# STM32MP25_CM33 register map
File version: 1.3
CPU: CM33 r0p1, little endian, MPU, FPU, vendor SysTick, 8 interrupt priority bits
Registers are 32-bit, read-write, reset 0x0 unless marked. A register's access mark holds for its fields unless they carry their own. Offsets are from the block's base; [hi:lo] are bit positions; {n}, {i} and the like mark numbered series; 'fields as' and 'values as' point back to an identical list.

## EXTI1 (part 1 of 2) — EXTI1 address block description
Base 0x44220000
Same registers: EXTI1_S 0x54220000
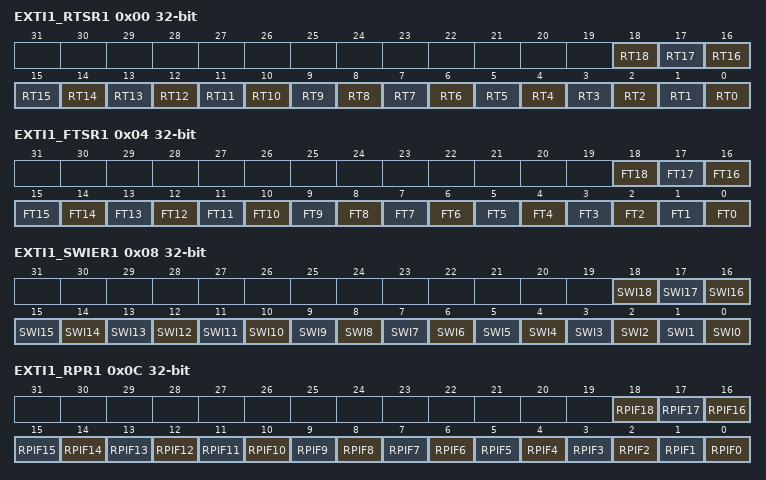
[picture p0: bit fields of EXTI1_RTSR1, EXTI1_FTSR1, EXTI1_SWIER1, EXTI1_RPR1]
0x00 EXTI1_RTSR1 — EXTI1 rising trigger selection register
  [all] fields
    0=Rising trigger disabled (for event and interrupt) for input line; 1=Rising trigger enabled (for event and interrupt) for input line
  [n] RT{n} (n=0..18) — Rising trigger event configuration bit of configurable event input x When SECx is disabled in EXTI1_SECCFGR1, RTx can be accessed with non-secure and secure access. When SECx is enabled in EXTI1_SECCFGR1, RTx can only be accessed with secure access. Non-secure write to RTx is discarded. Non-secure read returns 0. When PRIVx is disabled in EXTI1_PRIVCFGR1, RTx can be accessed with unprivileged and privileged access. When PRIVx is enabled in EXTI1_PRIVCFGR1, RTx can only be accessed with privileged access. Unprivileged write to RTx is discarded. Unprivileged read returns 0. When CID filtering is disabled in EXTI1_ExCIDCFGR, RTx can be accessed by any processor CID. When CID filtering is enabled in EXTI1_ExCIDCFGR, RTx can only be accessed by the allowed processor CID. Illegal CID write to RTx is discarded, and read returns 0. Note: The configurable event input is edge triggered. No glitch must be generated on this input. If a rising edge on the configurable event input occurs while writing to the register, the associated pending bit is not set. Note: Rising and falling edge triggers can be set for the same configurable event input. In this case, both edges generate a trigger.
0x04 EXTI1_FTSR1 — EXTI1 falling trigger selection register
  [all] fields
    0=Falling trigger disabled (for event and interrupt) for input line; 1=Falling trigger enabled (for event and interrupt) for input line
  [n] FT{n} (n=0..18) — Falling trigger event configuration bit of configurable event input x When SECx is disabled in EXTI1_SECCFGR1, FTx can be accessed with non-secure and secure access. When SECx is enabled in EXTI1_SECCFGR1, FTx can only be accessed with secure access. Non-secure write to FTx is discarded. Non-secure read returns 0. When PRIVx is disabled in EXTI1_PRIVCFGR1, FTx can be accessed with unprivileged and privileged access. When PRIVx is enabled in EXTI1_PRIVCFGR1, FTx can only be accessed with privileged access. Unprivileged write to FTx is discarded. Unprivileged read returns 0. When CID filtering is disabled in EXTI1_ExCIDCFGR, FTx can be accessed by any processor CID. When CID filtering is enabled in EXTI1_ExCIDCFGR, FTx can only be accessed by the allowed processor CID. Dis allowed CID CID write to FTx is discarded, and read returns0. Note: The configurable event input is edge triggered. No glitch must be generated on this input. If a falling edge on the configurable event input occurs while writing to the register, the associated pending bit is not set. Note: Rising and falling edge triggers can be set for the same configurable event input. In this case, both edges generate a trigger.
0x08 EXTI1_SWIER1 — EXTI1 software interrupt event register
  [all] fields
    0=Writing 0 has no effect; 1=Writing 1 to this bit triggers a rising edge event on event x (bit auto cleared byhardware)
  [n] SWI{n} (n=0..18) — Software interrupt on event x When SECx is disabled in EXTI1_SECCFGR1, SWIx can be accessed with non-secure and secure access. When SECx is enabled in EXTI1_SECCFGR1, SWIx can only be accessed with secure access. Non-secure write to SWIx is discarded. Non-secure read returns 0. When PRIVx is disabled in EXTI1_PRIVCFGR1,SWIx can be accessed with unprivileged and privileged access. When PRIVx is enabled in EXTI1_PRIVCFGR1,SWIx can only be accessed with privileged access. Unprivileged write to SWIx is discarded. Unprivileged read returns 0. When CID filtering is disabled in EXTI1_ExCIDCFGR, SWIx can be accessed by any processor CID. When CID filtering is enabled in EXTI1_ExCIDCFGR, SWIx can only be accessed by the allowed processor CID. Dis allowed CID write to SWIx is discarded and read returns0. A software interrupt is generated whatever the setting in EXTI1_RTSR and EXTI1_FTSR. It always returns 0 when read.
0x0C EXTI1_RPR1 — EXTI1 rising edge pending register
  [all] fields
    0=No rising edge trigger request occurred; 1=Rising edge trigger request occurred
  [n] RPIF{n} (n=0..18) — Configurable event input x rising edge pending bit This bit is set when the selected rising edge event or an EXTI1_SWIER software trigger arrives on the configurable event line. This bit is cleared by writing a 1 into the bit. When SECx is disabled in EXTI1_SECCFGR1, RPIFx can be accessed with non-secure and secure access. When SECx is enabled in EXTI1_SECCFGR1, RPIFx can only be accessed with secure access. Non-secure write to RPIFx is discarded. Non-secure read returns 0. When PRIVx is disabled in EXTI1_PRIVCFGR1, RPIFx can be accessed with unprivileged and privileged access. When PRIVx is enabled in EXTI1_PRIVCFGR1, RPIFx can only be accessed with privileged access. Unprivileged write to RPIFx is discarded. Unprivileged read returns 0. When CID filtering is disabled in EXTI1_ExCIDCFGR, RPIFx can be accessed by any processor CID. When CID filtering is enabled in EXTI1_ExCIDCFGR, RPIFx can only be accessed by the allowed processor CID. Dis allowed CID write to RPIFx is discarded, and read returns0.
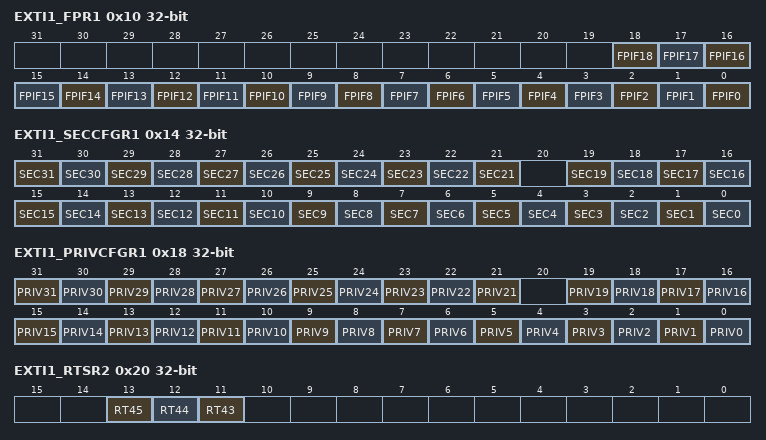
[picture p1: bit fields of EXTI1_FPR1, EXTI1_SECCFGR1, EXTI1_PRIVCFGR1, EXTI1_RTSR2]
0x10 EXTI1_FPR1 — EXTI1 falling edge pending register
  [all] fields
    0=No falling edge trigger request occurred; 1=Falling edge trigger request occurred
  [n] FPIF{n} (n=0..18) — configurable event input x falling edge pending bit This bit is set when the falling edge event arrives on the configurable event line. This bit is cleared by writing a 1 into this bit. When SECx is disabled in EXTI1_SECCFGR1, FPIFx can be accessed with non-secure and secure access. When SECx is enabled in EXTI1_SECCFGR1, FPIFx can only be accessed with secure access. Non-secure write to FPIFx is discarded. Non-secure read returns 0. When PRIVx is disabled in EXTI1_PRIVCFGR1, FPIFx can be accessed with unprivileged and privileged access. When PRIVx is enabled in EXTI1_PRIVCFGR1, FPIFx can only be accessed with privileged access. Unprivileged write to FPIFx is discarded. Unprivileged read returns 0. When CID filtering is disabled in EXTI1_ExCIDCFGR, FPIFx can be accessed by any processor CID. When CID filtering is enabled in EXTI1_ExCIDCFGR, FPIFx can only be accessed by the allowed processor CID. Dis allowed CID write to FPIFx is discarded, and read returns0.
0x14 EXTI1_SECCFGR1 — EXTI1 security configuration register
  [n] SEC{n} (n=21..31) — Security enable on event input x When CID filtering is disabled in EXTI1_ExCIDCFGR, SECx can be accessed by any processor CID. When CID filtering is enabled in EXTI1_ExCIDCFGR, SECx can only be accessed by the allowed processor CID. Dis allowed CID write to SECx is discarded and read returns 0.
    0=Event security disabled (non-secure); 1=Event security enabled (secure)
  [n] SEC{n} (n=0..19) — Security enable on event input x
0x18 EXTI1_PRIVCFGR1 — EXTI1 privilege configuration register
  [n] PRIV{n} (n=21..31) — Privilege enable on event input x When SECx is disabled in EXTI1_SECCFGR1, PRIVx can be accessed with secure and non-secure access. When SECx is enabled in EXTI1_SECCFGR1, PRIVx can only be written with secure access. Non-secure write to PRIVx is discarded. When CID filtering is disabled in EXTI1_ExCIDCFGR, PRIVx can be accessed by any processor CID. When CID filtering is enabled in EXTI1_ExCIDCFGR, PRIVx can only be accessed by the allowed processor CID. Dis allowed CID write to PRIVx is discarded and read returns 0.
    0=Event privilege disabled (unprivileged); 1=Event privilege enabled (privileged)
  [n] PRIV{n} (n=0..19) — Privilege enable on event input x
0x20 EXTI1_RTSR2 — EXTI1 rising trigger selection register
  [all] fields
    0=Rising trigger disabled (for event and Interrupt) for input line x; 1=Rising trigger enabled (for event and Interrupt) for input line x
  [13] RT45 — Rising trigger event configuration bit of configurable event input x When SECx is disabled in EXTI1_SECCFGR2, RTx can be accessed with non-secure and secure access. When SECx is enabled in EXTI1_SECCFGR2, RTx can only be accessed with secure access. Non-secure write to RTx is discarded. Non-secure read returns 0. When PRIVx is disabled in EXTI1_PRIVCFGR2, RTx can be accessed with unprivileged and privileged access. When PRIVx is enabled in EXTI1_PRIVCFGR2, RTx can only be accessed with privileged access. Unprivileged write to RTx is discarded. Unprivileged read returns 0. When CID filtering is disabled in EXTI1_ExCIDCFGR, RTx can be accessed by any processor CID. When CID filtering is enabled in EXTI1_ExCIDCFGR, RTx can only be accessed by the allowed processor CID. Illegal CID write to RTx is discarded and read returns 0. Note: The configurable event input is edge triggered. No glitch must be generated on this input. If a rising edge on the configurable event input occurs while writing to the register, the associated pending bit is not set. Note: Rising and falling edge triggers can be set for the same configurable event input. In this case, both edges generate a trigger.
  [12] RT44 — Rising trigger event configuration bit of configurable event input x When SECx is disabled in EXTI1_SECCFGR2, RTx can be accessed with non-secure and secure access. When SECx is enabled in EXTI1_SECCFGR2, RTx can only be accessed with secure access. Non-secure write to RTx is discarded. Non-secure read returns 0. When PRIVx is disabled in EXTI1_PRIVCFGR2, RTx can be accessed with unprivileged and privileged access. When PRIVx is enabled in EXTI1_PRIVCFGR2, RTx can only be accessed with privileged access. Unprivileged write to RTx is discarded. Unprivileged read returns 0. When CID filtering is disabled in EXTI1_ExCIDCFGR, RTx can be accessed by any processor CID. When CID filtering is enabled in EXTI1_ExCIDCFGR, RTx can only be accessed by the allowed processor CID. Illegal CID write to RTx is discarded and read returns 0. Note: The configurable event input is edge triggered. No glitch must be generated on this input. If a rising edge on the configurable event input occurs while writing to the register, the associated pending bit is not set. Note: Rising and falling edge triggers can be set for the same configurable event input. In this case, both edges generate a trigger.
  [11] RT43 — Rising trigger event configuration bit of configurable event input x When SECx is disabled in EXTI1_SECCFGR2, RTx can be accessed with non-secure and secure access. When SECx is enabled in EXTI1_SECCFGR2, RTx can only be accessed with secure access. Non-secure write to RTx is discarded. Non-secure read returns 0. When PRIVx is disabled in EXTI1_PRIVCFGR2, RTx can be accessed with unprivileged and privileged access. When PRIVx is enabled in EXTI1_PRIVCFGR2, RTx can only be accessed with privileged access. Unprivileged write to RTx is discarded. Unprivileged read returns 0. When CID filtering is disabled in EXTI1_ExCIDCFGR, RTx can be accessed by any processor CID. When CID filtering is enabled in EXTI1_ExCIDCFGR, RTx can only be accessed by the allowed processor CID. Illegal CID write to RTx is discarded and read returns 0. Note: The configurable event input is edge triggered. No glitch must be generated on this input. If a rising edge on the configurable event input occurs while writing to the register, the associated pending bit is not set. Note: Rising and falling edge triggers can be set for the same configurable event input. In this case, both edges generate a trigger.
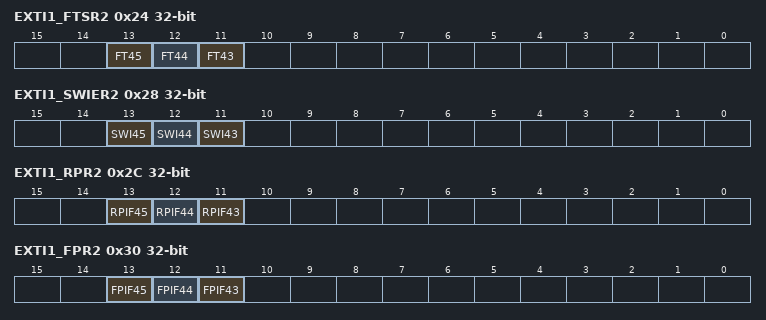
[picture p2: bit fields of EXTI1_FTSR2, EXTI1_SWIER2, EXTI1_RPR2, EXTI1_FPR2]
0x24 EXTI1_FTSR2 — EXTI1 falling trigger selection register
  [all] fields
    0=Falling trigger disabled (for event and Interrupt) for input line; 1=Falling trigger enabled (for event and Interrupt) for input line
  [13] FT45 — Falling trigger event configuration bit of configurable event input x When SECx is disabled in EXTI1_SECCFGR2, FTx can be accessed with non-secure and secure access. When SECx is enabled in EXTI1_SECCFGR2, FTx can only be accessed with secure access. Non-secure write to FTx is discarded. Non-secure read returns 0. When PRIVx is disabled in EXTI1_PRIVCFGR2, FTx can be accessed with unprivileged and privileged access. When PRIVx is enabled in EXTI1_PRIVCFGR2, FTx can only be accessed with privileged access. Unprivileged write to FTx is discarded. Unprivileged read returns 0. When CID filtering is disabled in EXTI1_ExCIDCFGR, FTx can be accessed by any processor CID. When CID filtering is enabled in EXTI1_ExCIDCFGR, FTx can only be accessed by the allowed processor CID. Dis allowed CID write to FTx is discarded and read returns 0. Note: The configurable event input is edge triggered. No glitch must be generated on this input. If a falling edge on the configurable event input occurs while writing to the register, the associated pending bit is not set. Note: Rising and falling edge triggers can be set for the same configurable event input. In this case, both edges generate a trigger.
  [12] FT44 — Falling trigger event configuration bit of configurable event input x When SECx is disabled in EXTI1_SECCFGR2, FTx can be accessed with non-secure and secure access. When SECx is enabled in EXTI1_SECCFGR2, FTx can only be accessed with secure access. Non-secure write to FTx is discarded. Non-secure read returns 0. When PRIVx is disabled in EXTI1_PRIVCFGR2, FTx can be accessed with unprivileged and privileged access. When PRIVx is enabled in EXTI1_PRIVCFGR2, FTx can only be accessed with privileged access. Unprivileged write to FTx is discarded. Unprivileged read returns 0. When CID filtering is disabled in EXTI1_ExCIDCFGR, FTx can be accessed by any processor CID. When CID filtering is enabled in EXTI1_ExCIDCFGR, FTx can only be accessed by the allowed processor CID. Dis allowed CID write to FTx is discarded and read returns 0. Note: The configurable event input is edge triggered. No glitch must be generated on this input. If a falling edge on the configurable event input occurs while writing to the register, the associated pending bit is not set. Note: Rising and falling edge triggers can be set for the same configurable event input. In this case, both edges generate a trigger.
  [11] FT43 — Falling trigger event configuration bit of configurable event input x When SECx is disabled in EXTI1_SECCFGR2, FTx can be accessed with non-secure and secure access. When SECx is enabled in EXTI1_SECCFGR2, FTx can only be accessed with secure access. Non-secure write to FTx is discarded. Non-secure read returns 0. When PRIVx is disabled in EXTI1_PRIVCFGR2, FTx can be accessed with unprivileged and privileged access. When PRIVx is enabled in EXTI1_PRIVCFGR2, FTx can only be accessed with privileged access. Unprivileged write to FTx is discarded. Unprivileged read returns 0. When CID filtering is disabled in EXTI1_ExCIDCFGR, FTx can be accessed by any processor CID. When CID filtering is enabled in EXTI1_ExCIDCFGR, FTx can only be accessed by the allowed processor CID. Dis allowed CID write to FTx is discarded and read returns 0. Note: The configurable event input is edge triggered. No glitch must be generated on this input. If a falling edge on the configurable event input occurs while writing to the register, the associated pending bit is not set. Note: Rising and falling edge triggers can be set for the same configurable event input. In this case, both edges generate a trigger.
0x28 EXTI1_SWIER2 — EXTI1 software interrupt event register
  [all] fields
    0=Writing 0 has no effect; 1=Writing 1 to this bit triggers a rising edge event on event x (bit auto cleared by hardware)
  [13] SWI45 — Software interrupt on event x When SECx is disabled in EXTI1_SECCFGR2, SWIx can be accessed with non-secure and secure access. When SECx is enabled in EXTI1_SECCFGR2, SWIx can only be accessed with secure access. Non-secure write to SWIx is discarded. Non-secure read returns 0. When PRIVx is disabled in EXTI1_PRIVCFGR2, SWIx can be accessed with unprivileged and privileged access. When PRIVx is enabled in EXTI1_PRIVCFGR2, SWIx can only be accessed with privileged access. Unprivileged write to SWIx is discarded. Unprivileged read returns 0. When CID filtering is disabled in EXTI1_ExCIDCFGR, SWIx can be accessed by any processor CID. When CID filtering is enabled in EXTI1_ExCIDCFGR, SWIx can only be accessed by the allowed processor CID. Dis allowed CID write to SWIx is discarded and read returns 0. A software interrupt is generated whatever the setting in EXTI1_RTSR and EXTI1_FTSR. It always returns 0 when read.
  [12] SWI44 — Software interrupt on event x When SECx is disabled in EXTI1_SECCFGR2, SWIx can be accessed with non-secure and secure access. When SECx is enabled in EXTI1_SECCFGR2, SWIx can only be accessed with secure access. Non-secure write to SWIx is discarded. Non-secure read returns 0. When PRIVx is disabled in EXTI1_PRIVCFGR2, SWIx can be accessed with unprivileged and privileged access. When PRIVx is enabled in EXTI1_PRIVCFGR2, SWIx can only be accessed with privileged access. Unprivileged write to SWIx is discarded. Unprivileged read returns 0. When CID filtering is disabled in EXTI1_ExCIDCFGR, SWIx can be accessed by any processor CID. When CID filtering is enabled in EXTI1_ExCIDCFGR, SWIx can only be accessed by the allowed processor CID. Dis allowed CID write to SWIx is discarded and read returns 0. A software interrupt is generated whatever the setting in EXTI1_RTSR and EXTI1_FTSR. It always returns 0 when read.
  [11] SWI43 — Software interrupt on event x When SECx is disabled in EXTI1_SECCFGR2, SWIx can be accessed with non-secure and secure access. When SECx is enabled in EXTI1_SECCFGR2, SWIx can only be accessed with secure access. Non-secure write to SWIx is discarded. Non-secure read returns 0. When PRIVx is disabled in EXTI1_PRIVCFGR2, SWIx can be accessed with unprivileged and privileged access. When PRIVx is enabled in EXTI1_PRIVCFGR2, SWIx can only be accessed with privileged access. Unprivileged write to SWIx is discarded. Unprivileged read returns 0. When CID filtering is disabled in EXTI1_ExCIDCFGR, SWIx can be accessed by any processor CID. When CID filtering is enabled in EXTI1_ExCIDCFGR, SWIx can only be accessed by the allowed processor CID. Dis allowed CID write to SWIx is discarded and read returns 0. A software interrupt is generated whatever the setting in EXTI1_RTSR and EXTI1_FTSR. It always returns 0 when read.
0x2C EXTI1_RPR2 — EXTI1 rising edge pending register
  [all] fields
    values as the fields of EXTI1_RPR1
  [13] RPIF45 — Configurable event input x rising edge pending bit This bit is set when the selected rising edge event or an EXTI1_SWIER software trigger arrives on the configurable event line. This bit is cleared by writing a 1 into the bit. When SECx is disabled in EXTI1_SECCFGR2, RPIFx can be accessed with non-secure and secure access. When SECx is enabled in EXTI1_SECCFGR2, RPIFx can only be accessed with secure access. Non-secure write to RPIFx is discarded. Non-secure read returns 0. When PRIVx is disabled in EXTI1_PRIVCFGR2, RPIFx can be accessed with unprivileged and privileged access. When PRIVx is enabled in EXTI1_PRIVCFGR2, this bit can only be accessed with privileged access. Unprivileged write to RPIFx is discarded. Unprivileged read returns 0. When CID filtering is disabled in EXTI1_ExCIDCFGR, RPIFx can be accessed by any processor CID. When CID filtering is enabled in EXTI1_ExCIDCFGR, this bit can only be accessed by the allowed processor CID. Dis allowed CID write to RPIFx is discarded and read returns 0.
  [12] RPIF44 — Configurable event input x rising edge pending bit This bit is set when the selected rising edge event or an EXTI1_SWIER software trigger arrives on the configurable event line. This bit is cleared by writing a 1 into the bit. When SECx is disabled in EXTI1_SECCFGR2, RPIFx can be accessed with non-secure and secure access. When SECx is enabled in EXTI1_SECCFGR2, RPIFx can only be accessed with secure access. Non-secure write to RPIFx is discarded. Non-secure read returns 0. When PRIVx is disabled in EXTI1_PRIVCFGR2, RPIFx can be accessed with unprivileged and privileged access. When PRIVx is enabled in EXTI1_PRIVCFGR2, this bit can only be accessed with privileged access. Unprivileged write to RPIFx is discarded. Unprivileged read returns 0. When CID filtering is disabled in EXTI1_ExCIDCFGR, RPIFx can be accessed by any processor CID. When CID filtering is enabled in EXTI1_ExCIDCFGR, this bit can only be accessed by the allowed processor CID. Dis allowed CID write to RPIFx is discarded and read returns 0.
  [11] RPIF43 — Configurable event input x rising edge pending bit This bit is set when the selected rising edge event or an EXTI1_SWIER software trigger arrives on the configurable event line. This bit is cleared by writing a 1 into the bit. When SECx is disabled in EXTI1_SECCFGR2, RPIFx can be accessed with non-secure and secure access. When SECx is enabled in EXTI1_SECCFGR2, RPIFx can only be accessed with secure access. Non-secure write to RPIFx is discarded. Non-secure read returns 0. When PRIVx is disabled in EXTI1_PRIVCFGR2, RPIFx can be accessed with unprivileged and privileged access. When PRIVx is enabled in EXTI1_PRIVCFGR2, this bit can only be accessed with privileged access. Unprivileged write to RPIFx is discarded. Unprivileged read returns 0. When CID filtering is disabled in EXTI1_ExCIDCFGR, RPIFx can be accessed by any processor CID. When CID filtering is enabled in EXTI1_ExCIDCFGR, this bit can only be accessed by the allowed processor CID. Dis allowed CID write to RPIFx is discarded and read returns 0.
0x30 EXTI1_FPR2 — EXTI1 falling edge pending register
  [all] fields
    values as the fields of EXTI1_FPR1
  [13] FPIF45 — Configurable event input x falling edge pending bit This bit is set when the falling edge event arrives on the configurable event line. This bit is cleared by writing a 1 into the bit. When SECx is disabled in EXTI1_SECCFGR2, FPIFx can be accessed with non-secure and secure access. When SECx is enabled in EXTI1_SECCFGR2, FPIFx can only be accessed with secure access. Non-secure write to this FPIFx is discarded. Non-secure read returns 0. When PRIVx is disabled in EXTI1_PRIVCFGR2d, FPIFx can be accessed with unprivileged and privileged access. When PRIVx is enabled in EXTI1_PRIVCFGR2, FPIFx can only be accessed with privileged access. Unprivileged write to FPIFx is discarded. Unprivileged read returns 0. When CID filtering is disabled in EXTI1_ExCIDCFGR, FPIFx can be accessed by any processor CID. When CID filtering is enabled in EXTI1_ExCIDCFGR, this bit can only be accessed by the allowed processor CID. Dis allowed CID write to FPIFx is discarded and read returns 0.
  [12] FPIF44 — Configurable event input x falling edge pending bit This bit is set when the falling edge event arrives on the configurable event line. This bit is cleared by writing a 1 into the bit. When SECx is disabled in EXTI1_SECCFGR2, FPIFx can be accessed with non-secure and secure access. When SECx is enabled in EXTI1_SECCFGR2, FPIFx can only be accessed with secure access. Non-secure write to this FPIFx is discarded. Non-secure read returns 0. When PRIVx is disabled in EXTI1_PRIVCFGR2d, FPIFx can be accessed with unprivileged and privileged access. When PRIVx is enabled in EXTI1_PRIVCFGR2, FPIFx can only be accessed with privileged access. Unprivileged write to FPIFx is discarded. Unprivileged read returns 0. When CID filtering is disabled in EXTI1_ExCIDCFGR, FPIFx can be accessed by any processor CID. When CID filtering is enabled in EXTI1_ExCIDCFGR, this bit can only be accessed by the allowed processor CID. Dis allowed CID write to FPIFx is discarded and read returns 0.
  [11] FPIF43 — Configurable event input x falling edge pending bit This bit is set when the falling edge event arrives on the configurable event line. This bit is cleared by writing a 1 into the bit. When SECx is disabled in EXTI1_SECCFGR2, FPIFx can be accessed with non-secure and secure access. When SECx is enabled in EXTI1_SECCFGR2, FPIFx can only be accessed with secure access. Non-secure write to this FPIFx is discarded. Non-secure read returns 0. When PRIVx is disabled in EXTI1_PRIVCFGR2d, FPIFx can be accessed with unprivileged and privileged access. When PRIVx is enabled in EXTI1_PRIVCFGR2, FPIFx can only be accessed with privileged access. Unprivileged write to FPIFx is discarded. Unprivileged read returns 0. When CID filtering is disabled in EXTI1_ExCIDCFGR, FPIFx can be accessed by any processor CID. When CID filtering is enabled in EXTI1_ExCIDCFGR, this bit can only be accessed by the allowed processor CID. Dis allowed CID write to FPIFx is discarded and read returns 0.
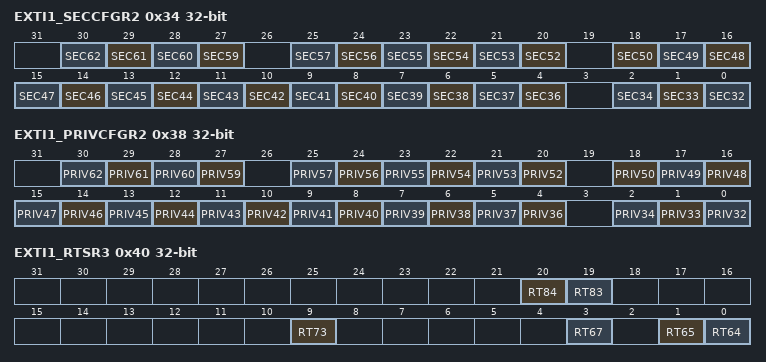
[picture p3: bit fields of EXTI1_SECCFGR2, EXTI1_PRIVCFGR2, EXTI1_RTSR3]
0x34 EXTI1_SECCFGR2 — EXTI1 security enable register
  [n-32] SEC{n} (n=59..62) — Security enable on event input x When CID filtering is disabled in EXTI1_ExCIDCFGR, SECx can be accessed by any processor CID. When CID filtering is enabled in EXTI1_ExCIDCFGR, SECx can only be accessed by the allowed processor CID. Dis allowed CID write to SECx is discarded and read returns 0.
    values as EXTI1_SECCFGR1.SEC21
  [n-32] SEC{n} (n=52..57) — Security enable on event input x
  [n-32] SEC{n} (n=36..50) — Security enable on event input x
  [2] SEC34 — Security enable on event input x
  [1] SEC33 — Security enable on event input x
  [0] SEC32 — Security enable on event input x
0x38 EXTI1_PRIVCFGR2 — EXTI1 privilege enable register
  [n-32] PRIV{n} (n=59..62) — Privilege enable on event input x When SECx is disabled in EXTI1_SECCFGR2, PRIVx can be accessed with secure and non-secure access. When SECx is enabled in EXTI1_SECCFGR2, PRIVx can only be accessed with secure access. Non-secure write to PRIVx is discarded. When CID filtering is disabled in EXTI1_ExCIDCFGR, PRIVx can be accessed by any processor CID. When CID filtering is enabled in EXTI1_ExCIDCFGR, PRIVx can only be accessed by the allowed processor CID. Dis allowed CID write to PRIVx is discarded, and read returns 0.
    values as EXTI1_PRIVCFGR1.PRIV21
  [n-32] PRIV{n} (n=52..57) — Privilege enable on event input x
  [n-32] PRIV{n} (n=36..50) — Privilege enable on event input x
  [2] PRIV34 — Privilege enable on event input x
  [1] PRIV33 — Privilege enable on event input x
  [0] PRIV32 — Privilege enable on event input x
0x40 EXTI1_RTSR3 — EXTI1 rising trigger selection register
  [20] RT84 — Rising trigger event configuration bit of configurable event input x When SECx is disabled in EXTI1_SECCFGR3, RTx can be accessed with non-secure and secure access. When SECx is enabled in EXTI1_SECCFGR3, RTx can only be accessed with secure access. Non-secure write to RTx is discarded. Non-secure read returns 0. When PRIVx i disabled in EXTI1_PRIVCFGR3, RTx can be accessed with unprivileged and privileged access. When PRIVx is enabled in EXTI1_PRIVCFGR3, RTx can only be accessed with privileged access. Unprivileged write to RTx is discarded. Unprivileged read returns 0. When CID filtering is disabled in EXTI1_ExCIDCFGR, RTx can be accessed by any processor CID. When CID filtering is enabled in EXTI1_ExCIDCFGR, RTx can only be accessed by the allowed processor CID. Dis allowed CID write to RTx is discarded, and read returns 0. Note: The configurable event input is edge triggered. No glitch must be generated on this input. If a rising edge on the configurable event input occurs while writing to the register, the associated pending bit is not set. Note: Rising and falling edge triggers can be set for the same configurable event input. In this case, both edges generate a trigger.
    values as the fields of EXTI1_RTSR1
  [19] RT83 — Rising trigger event configuration bit of configurable event input x When SECx is disabled in EXTI1_SECCFGR3, RTx can be accessed with non-secure and secure access. When SECx is enabled in EXTI1_SECCFGR3, RTx can only be accessed with secure access. Non-secure write to RTx is discarded. Non-secure read returns 0. When PRIVx i disabled in EXTI1_PRIVCFGR3, RTx can be accessed with unprivileged and privileged access. When PRIVx is enabled in EXTI1_PRIVCFGR3, RTx can only be accessed with privileged access. Unprivileged write to RTx is discarded. Unprivileged read returns 0. When CID filtering is disabled in EXTI1_ExCIDCFGR, RTx can be accessed by any processor CID. When CID filtering is enabled in EXTI1_ExCIDCFGR, RTx can only be accessed by the allowed processor CID. Dis allowed CID write to RTx is discarded, and read returns 0. Note: The configurable event input is edge triggered. No glitch must be generated on this input. If a rising edge on the configurable event input occurs while writing to the register, the associated pending bit is not set. Note: Rising and falling edge triggers can be set for the same configurable event input. In this case, both edges generate a trigger.
    values as the fields of EXTI1_RTSR1
  [9] RT73 — Rising trigger event configuration bit of configurable event input 73
  [3] RT67 — Rising trigger event configuration bit of configurable event input 67
  [1] RT65 — Rising trigger event configuration bit of configurable event input x
  [0] RT64 — Rising trigger event configuration bit of configurable event input x
